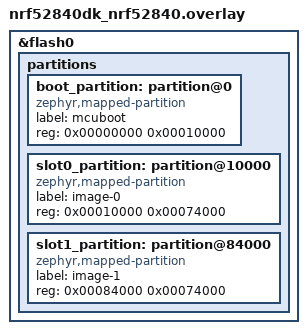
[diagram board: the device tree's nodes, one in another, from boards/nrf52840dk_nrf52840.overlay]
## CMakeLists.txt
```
# keelsign_hello (SHA-62): an application MCUboot boots only after keelsign verified its
# LMS/HSS signature. docs/mcuboot.md.
#
# SPDX-License-Identifier: MIT OR Apache-2.0

cmake_minimum_required(VERSION 3.20.0)

find_package(Zephyr REQUIRED HINTS $ENV{ZEPHYR_BASE})
project(keelsign_hello)

# Built through sysbuild only, so MCUboot (with keelsign) is part of the build.
test_sysbuild()

target_sources(app PRIVATE src/main.c)
```

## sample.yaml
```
sample:
  description: MCUboot verifying keelsign's post-quantum (LMS/HSS) signature
  name: keelsign hello
tests:
  sample.keelsign.hello:
    sysbuild: true
    platform_allow:
      - nrf52840dk/nrf52840
    integration_platforms:
      - nrf52840dk/nrf52840
    tags: mcuboot keelsign
    harness: console
    harness_config:
      type: multi_line
      regex:
        - "keelsign: image 0 slot 0 verified (.*)"
        - "hello from keelsign_hello(.*)"
```

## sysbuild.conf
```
# keelsign_hello sysbuild configuration (docs/mcuboot.md).
#
# MCUboot with its own ECDSA P-256 signature (imgtool, the key file sysbuild defaults
# to: MCUboot's root-ec-p256.pem, for development only) ...
SB_CONFIG_BOOTLOADER_MCUBOOT=y
SB_CONFIG_BOOT_SIGNATURE_TYPE_ECDSA_P256=y
# ... and keelsign's LMS/HSS signature on top, verified in MCUboot's image-check hook
# under the post-quantum-only policy. keelsign-dev.pem (+ .state, .journal) is made in
# this directory by `keelsign keygen --alg lms-sha256-m32-h10 --out keelsign-dev.pem`
# and never committed (.gitignore).
SB_CONFIG_KEELSIGN=y
SB_CONFIG_KEELSIGN_SIGNATURE_KEY_FILE="keelsign-dev.pem"
SB_CONFIG_KEELSIGN_POLICY_PQ_ONLY=y
```

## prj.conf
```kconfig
# keelsign_hello application: console output only.
CONFIG_PRINTK=y
```

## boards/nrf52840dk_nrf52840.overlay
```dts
/*
 * keelsign_hello partitions on nrf52840dk/nrf52840 (SHA-62, docs/mcuboot.md#partitions):
 * a 64 KB boot partition (MCUboot plus keelsign's LMS/HSS verifier; the board's default
 * is 48 KB), two 464 KB image slots, the 32 KB storage partition unchanged. The MCUboot
 * image includes this file from sysbuild/mcuboot.overlay, so both images always agree.
 *
 * SPDX-License-Identifier: MIT OR Apache-2.0
 */

/delete-node/ &boot_partition;
/delete-node/ &slot0_partition;
/delete-node/ &slot1_partition;

&flash0 {
	partitions {
		boot_partition: partition@0 {
			compatible = "zephyr,mapped-partition";
			label = "mcuboot";
			reg = <0x00000000 0x00010000>;
		};

		slot0_partition: partition@10000 {
			compatible = "zephyr,mapped-partition";
			label = "image-0";
			reg = <0x00010000 0x00074000>;
		};

		slot1_partition: partition@84000 {
			compatible = "zephyr,mapped-partition";
			label = "image-1";
			reg = <0x00084000 0x00074000>;
		};
	};
};
```

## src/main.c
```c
/*
 * keelsign_hello (SHA-62): prints that it runs and where it was linked (the start of
 * its ROM region: slot 0, where the image header is), then ticks.
 * MCUboot only gets here after keelsign verified the image's LMS/HSS signature and
 * MCUboot verified its own (docs/mcuboot.md).
 *
 * SPDX-License-Identifier: MIT OR Apache-2.0
 */
#include <zephyr/kernel.h>
#include <zephyr/linker/linker-defs.h>
#include <zephyr/sys/printk.h>

int main(void)
{
	unsigned int tick = 0;

	printk("hello from keelsign_hello on %s, linked at %p\n", CONFIG_BOARD,
	       (void *)__rom_region_start);
	for (;;) {
		k_sleep(K_SECONDS(1));
		printk("keelsign_hello tick %u\n", ++tick);
	}
	return 0;
}
```
